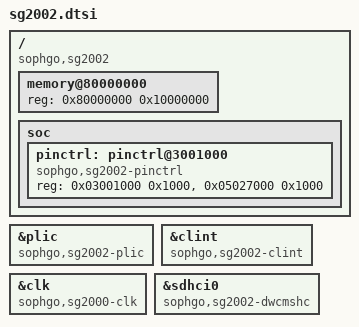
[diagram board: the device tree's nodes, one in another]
// SPDX-License-Identifier: (GPL-2.0 OR MIT)
/*
 * Copyright (C) 2024 Thomas Bonnefille <thomas.bonnefille@bootlin.com>
 */

#include <dt-bindings/interrupt-controller/irq.h>
#include <dt-bindings/pinctrl/pinctrl-sg2002.h>
#include "cv18xx.dtsi"
#include "cv181x.dtsi"

/ {
	compatible = "sophgo,sg2002";

	memory@80000000 {
		device_type = "memory";
		reg = <0x80000000 0x10000000>;
	};

	soc {
		pinctrl: pinctrl@3001000 {
			compatible = "sophgo,sg2002-pinctrl";
			reg = <0x03001000 0x1000>,
			      <0x05027000 0x1000>;
			reg-names = "sys", "rtc";
		};
	};
};

&plic {
	compatible = "sophgo,sg2002-plic", "thead,c900-plic";
};

&clint {
	compatible = "sophgo,sg2002-clint", "thead,c900-clint";
};

&clk {
	compatible = "sophgo,sg2000-clk";
};

&sdhci0 {
	compatible = "sophgo,sg2002-dwcmshc";
};
